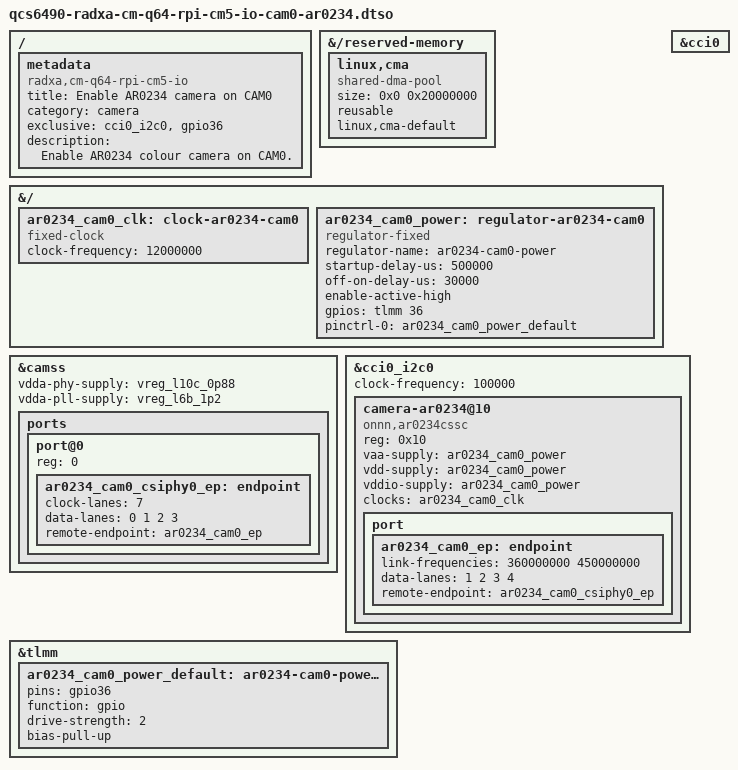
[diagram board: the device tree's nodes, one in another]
// SPDX-License-Identifier: BSD-3-Clause
/*
 * Copyright (c) 2025 Radxa Computer (Shenzhen) Co., Ltd.
 */

/dts-v1/;
/plugin/;

#include <dt-bindings/gpio/gpio.h>

/ {
	metadata {
		title = "Enable AR0234 camera on CAM0";
		compatible = "radxa,cm-q64-rpi-cm5-io";
		category = "camera";
		exclusive = "cci0_i2c0", "gpio36";
		description = "Enable AR0234 colour camera on CAM0.";
	};
};

&{/reserved-memory} {
	linux,cma {
		compatible = "shared-dma-pool";
		size = <0x0 0x20000000>;
		reusable;
		linux,cma-default;
	};
};

&{/} {
	ar0234_cam0_clk: clock-ar0234-cam0 {
		compatible = "fixed-clock";
		#clock-cells = <0>;
		clock-frequency = <12000000>;
	};

	/* Model the module's shared power enable, not its individual rail voltages. */
	ar0234_cam0_power: regulator-ar0234-cam0 {
		status = "okay";
		compatible = "regulator-fixed";
		regulator-name = "ar0234-cam0-power";
		startup-delay-us = <500000>;
		off-on-delay-us = <30000>;
		enable-active-high;
		gpios = <&tlmm 36 GPIO_ACTIVE_HIGH>;
		pinctrl-names = "default";
		pinctrl-0 = <&ar0234_cam0_power_default>;
	};
};

&camss {
	vdda-phy-supply = <&vreg_l10c_0p88>;
	vdda-pll-supply = <&vreg_l6b_1p2>;

	status = "okay";

	ports {
		#address-cells = <1>;
		#size-cells = <0>;

		/* The port index denotes CSIPHY0. */
		port@0 {
			reg = <0>;

			ar0234_cam0_csiphy0_ep: endpoint {
				/* SC7280 receiver indices differ from sensor lane numbers. */
				clock-lanes = <7>;
				data-lanes = <0 1 2 3>;
				remote-endpoint = <&ar0234_cam0_ep>;
			};
		};
	};
};

&cci0 {
	status = "okay";
};

&cci0_i2c0 {
	#address-cells = <1>;
	#size-cells = <0>;

	status = "okay";
	clock-frequency = <100000>;

	camera-ar0234@10 {
		compatible = "onnn,ar0234cssc";
		reg = <0x10>;

		/*
		 * VAA, VDD and VDDIO are generated on the module and share the
		 * GPIO36 power enable. Their individual voltages are not specified.
		 */
		vaa-supply = <&ar0234_cam0_power>;
		vdd-supply = <&ar0234_cam0_power>;
		vddio-supply = <&ar0234_cam0_power>;

		clocks = <&ar0234_cam0_clk>;

		port {
			ar0234_cam0_ep: endpoint {
				link-frequencies = /bits/ 64 <360000000 450000000>;
				data-lanes = <1 2 3 4>;
				remote-endpoint = <&ar0234_cam0_csiphy0_ep>;
			};
		};
	};
};

&tlmm {
	ar0234_cam0_power_default: ar0234-cam0-power-default-state {
		pins = "gpio36";
		function = "gpio";
		drive-strength = <2>;
		bias-pull-up;
	};
};
